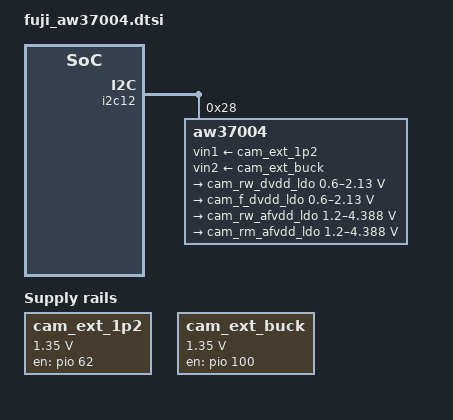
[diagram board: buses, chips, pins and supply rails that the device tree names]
&odm{
    cam_ext_1p2: gpio62-fixed {
        compatible = "regulator-fixed";
        regulator-name = "vcam_ext_1p2_gpio_regulator";
        regulator-min-microvolt = <1350000>;
        regulator-max-microvolt = <1350000>;
        enable-active-high;
        regulator-always-on;
        regulator-boot-on;
        gpio = <&pio 62 0x0>;
    };

     cam_ext_buck: gpio100-fixed {
        compatible = "regulator-fixed";
        regulator-name = "vcam_common_buck_regulator";
        regulator-min-microvolt = <1350000>;
        regulator-max-microvolt = <1350000>;
        enable-active-high;
        regulator-always-on;
        regulator-boot-on;
        gpio = <&pio 100 0x0>;
    };

};

&i2c12{
    aw37004: aw37004@28 {
        status = "okay";
        compatible = "aw37004";
        reg = <0x28>;
        vin1-supply = <&cam_ext_1p2>;
        vin2-supply = <&cam_ext_buck>;
        init-value = <0x00>;
        regulators{
            cam_rw_dvdd_ldo: ldo1 {
                regulator-name = "aw37004_ldo1";
                regulator-min-microvolt = <600000>;
                regulator-max-microvolt = <2130000>;
            };

            cam_f_dvdd_ldo: ldo2 {
                regulator-name = "aw37004_ldo2";
                regulator-min-microvolt = <600000>;
                regulator-max-microvolt = <2130000>;

            };

            cam_rw_afvdd_ldo: ldo3 {
                regulator-name = "aw37004_ldo3";
                regulator-min-microvolt = <1200000>;
                regulator-max-microvolt = <4387500>;

            };

            cam_rm_afvdd_ldo: ldo4 {
                regulator-name = "aw37004_ldo4";
                regulator-min-microvolt = <1200000>;
                regulator-max-microvolt = <4387500>;

            };
        };
    };
};
